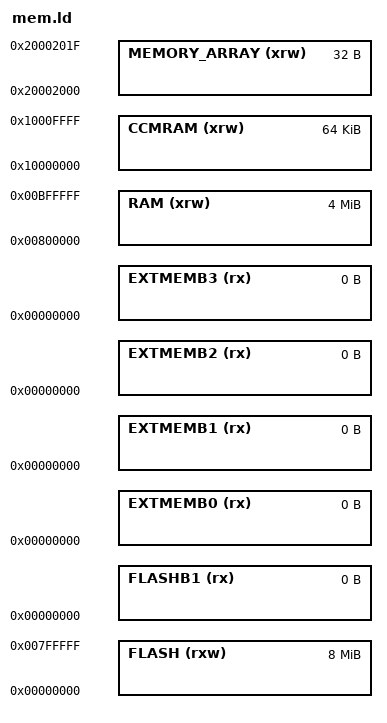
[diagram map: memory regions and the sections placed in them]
/*
 * Memory Spaces Definitions.
 *
 * Need modifying for a specific board. 
 *   FLASH.ORIGIN: starting address of flash
 *   FLASH.LENGTH: length of flash
 *   RAM.ORIGIN: starting address of RAM bank 0
 *   RAM.LENGTH: length of RAM bank 0
 *
 * The values below can be addressed in further linker scripts
 * using functions like 'ORIGIN(RAM)' or 'LENGTH(RAM)'.
 */

MEMORY
{
  FLASH (rxw) : ORIGIN = 0x00000000, LENGTH = 8192k
  RAM (xrw) : ORIGIN = 0x00000000+8192k, LENGTH = 4096k
  CCMRAM (xrw) : ORIGIN = 0x10000000, LENGTH = 64K
  FLASHB1 (rx) : ORIGIN = 0x00000000, LENGTH = 0
  EXTMEMB0 (rx) : ORIGIN = 0x00000000, LENGTH = 0
  EXTMEMB1 (rx) : ORIGIN = 0x00000000, LENGTH = 0
  EXTMEMB2 (rx) : ORIGIN = 0x00000000, LENGTH = 0
  EXTMEMB3 (rx) : ORIGIN = 0x00000000, LENGTH = 0
  MEMORY_ARRAY (xrw)  : ORIGIN = 0x20002000, LENGTH = 32
}

/*
 * For external ram use something like:

   RAM (xrw) : ORIGIN = 0x64000000, LENGTH = 2048K

 */
